# f2838x_cm_mcan_error_regs register map
Vendor: Texas Instruments
Peripheral module from a debugger description file (folder C2000).
Address unit: 16 bits
Registers are 32-bit, read-write, no defined reset value unless marked. A register's access mark holds for its fields unless they carry their own. Offsets are as the file gives them; lines under a group give offsets from that group; [hi:lo] are bit positions; {n}, {i} and the like mark numbered series; 'fields as' and 'values as' point back to an identical list; <NAME> marks a mode.

## MCAN_ERROR_REGS — MCAN ERROR Registers
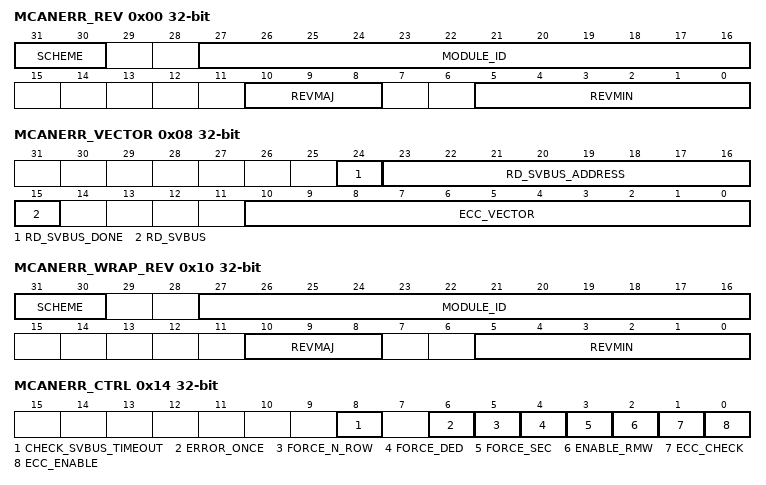
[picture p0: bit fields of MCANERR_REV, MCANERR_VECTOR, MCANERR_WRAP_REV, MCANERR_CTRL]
0x00 MCANERR_REV ro — MCAN Error Aggregator Revision Register
  [31:30] SCHEME — PID Register Scheme
  [27:16] MODULE_ID — Module Identification Number
  [10:8] REVMAJ — Major Revision
  [5:0] REVMIN — Minor Revision
0x08 MCANERR_VECTOR access per field — MCAN ECC Vector Register
  [24] RD_SVBUS_DONE ro — Read Completion Flag
  [23:16] RD_SVBUS_ADDRESS rw — Read Address Offset
  [15] RD_SVBUS rw — Read Trigger
  [10:0] ECC_VECTOR rw — ECC RAM ID
0x0C MCANERR_STAT ro — MCAN Error Misc Status
  [10:0] NUM_RAMS — Number of RAMs
0x10 MCANERR_WRAP_REV ro — MCAN ECC Wrapper Revision Register
  fields as MCANERR_REV
0x14 MCANERR_CTRL — MCAN ECC Control
  [8] CHECK_SVBUS_TIMEOUT — SVBUS Timeout Enable
  [6] ERROR_ONCE — Force Error Only Once Enable
  [5] FORCE_N_ROW — Force Next Single/Double Bit Error
  [4] FORCE_DED — Force Double Bit Error Detected Error
  [3] FORCE_SEC — Force Single Bit Error Corrected Error
  [2] ENABLE_RMW — Enable Read-Modify-Write
  [1] ECC_CHECK — Enable ECC Check
  [0] ECC_ENABLE — Enable ECC Generation
0x18 MCANERR_ERR_CTRL1 — MCAN ECC Error Control 1 Register
  [31:0] ECC_ROW — Force Error Row Address
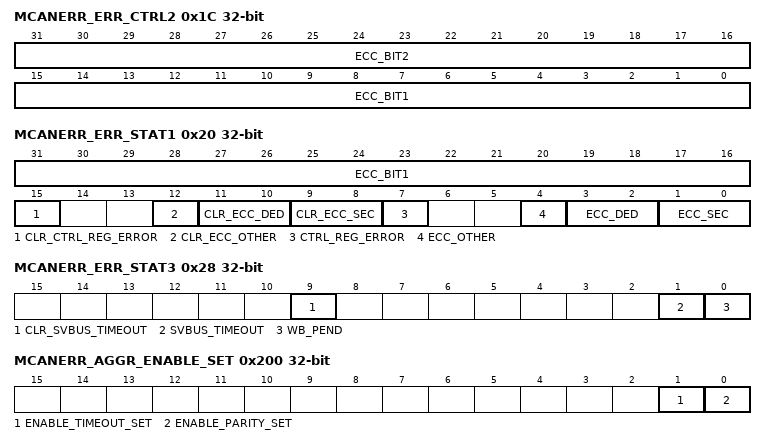
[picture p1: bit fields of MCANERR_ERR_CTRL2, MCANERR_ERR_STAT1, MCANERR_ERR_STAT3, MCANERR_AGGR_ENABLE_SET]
0x1C MCANERR_ERR_CTRL2 — MCAN ECC Error Control 2 Register
  [31:16] ECC_BIT2 — Force Error Bit2 Column Index
  [15:0] ECC_BIT1 — Force Error Bit1 Column Index
0x20 MCANERR_ERR_STAT1 access per field — MCAN ECC Error Status 1 Register
  [31:16] ECC_BIT1 ro — ECC Error Bit Position
  [15] CLR_CTRL_REG_ERROR rw — Clear Control Register Error
  [12] CLR_ECC_OTHER rw — Clear ECC_OTHER
  [11:10] CLR_ECC_DED rw — Clear ECC_DED
  [9:8] CLR_ECC_SEC rw — Clear ECC_SEC
  [7] CTRL_REG_ERROR rw — Control Register Error
  [4] ECC_OTHER rw — SEC While Writeback Error Status
  [3:2] ECC_DED rw — Double Bit Error Detected Status
  [1:0] ECC_SEC rw — Single Bit Error Corrected Status
0x24 MCANERR_ERR_STAT2 ro — MCAN ECC Error Status 2 Register
  [31:0] ECC_ROW — ECC Error Row Address
0x28 MCANERR_ERR_STAT3 access per field — MCAN ECC Error Status 3 Register
  [9] CLR_SVBUS_TIMEOUT rw — Clear Serial VBUS Timeout
  [1] SVBUS_TIMEOUT rw — Serial VBUS Timeout Flag
  [0] WB_PEND ro — Delayed Write Back Pending Status
0x3C MCANERR_SEC_EOI — MCAN Single Error Corrected End of Interrupt Register
  [0] EOI_WR — End of Interrupt
0x40 MCANERR_SEC_STATUS — MCAN Single Error Corrected Interrupt Status Register
  [0] MSGMEM_PEND — Message RAM SEC Interrupt Pending
0x80 MCANERR_SEC_ENABLE_SET — MCAN Single Error Corrected Interrupt Enable Set Register
  [0] MSGMEM_ENABLE_SET — Message RAM SEC Interrupt Pending Enable Set
0xC0 MCANERR_SEC_ENABLE_CLR — MCAN Single Error Corrected Interrupt Enable Clear Register
  [0] MSGMEM_ENABLE_CLR — Message RAM SEC Interrupt Pending Enable Clear
0x13C MCANERR_DED_EOI — MCAN Double Error Detected End of Interrupt Register
  [0] EOI_WR — End of Interrupt
0x140 MCANERR_DED_STATUS — MCAN Double Error Detected Interrupt Status Register
  [0] MSGMEM_PEND — Message RAM DED Interrupt Pending
0x180 MCANERR_DED_ENABLE_SET — MCAN Double Error Detected Interrupt Enable Set Register
  [0] MSGMEM_ENABLE_SET — Message RAM DED Interrupt Pending Enable Set
0x1C0 MCANERR_DED_ENABLE_CLR — MCAN Double Error Detected Interrupt Enable Clear Register
  [0] MSGMEM_ENABLE_CLR — Message RAM DED Interrupt Pending Enable Clear
0x200 MCANERR_AGGR_ENABLE_SET — MCAN Error Aggregator Enable Set Register
  [1] ENABLE_TIMEOUT_SET — Enable Timeout Errors Set
  [0] ENABLE_PARITY_SET — Enable Parity Errors Set
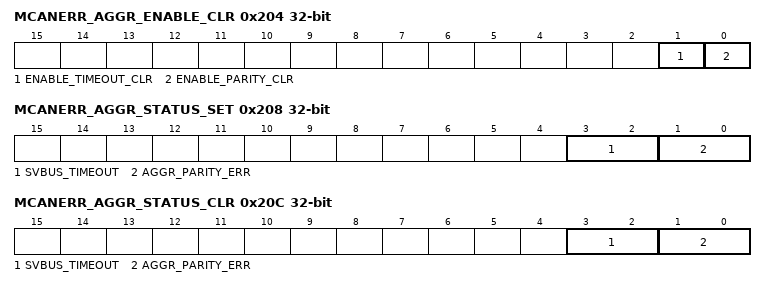
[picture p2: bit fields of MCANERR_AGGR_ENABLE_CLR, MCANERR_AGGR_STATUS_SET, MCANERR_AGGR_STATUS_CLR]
0x204 MCANERR_AGGR_ENABLE_CLR — MCAN Error Aggregator Enable Clear Register
  [1] ENABLE_TIMEOUT_CLR — Enable Timeout Errors Clear
  [0] ENABLE_PARITY_CLR — Enable Parity Errors Clear
0x208 MCANERR_AGGR_STATUS_SET — MCAN Error Aggregator Status Set Register
  [3:2] SVBUS_TIMEOUT — Aggregator Serial VBUS Timeout Error Status
  [1:0] AGGR_PARITY_ERR — Aggregator Parity Error Status
0x20C MCANERR_AGGR_STATUS_CLR — MCAN Error Aggregator Status Clear Register
  fields as MCANERR_AGGR_STATUS_SET
